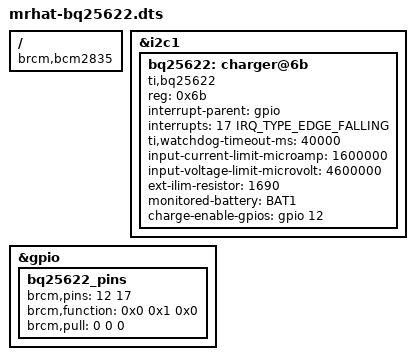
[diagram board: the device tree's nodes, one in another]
/*
* Copyright (C) 2024 Effective Range Kft.
*
* This program is free software; you can redistribute it and/or modify
* it under the terms of the GNU General Public License version 2 as
* published by the Free Software Foundation.
*/
/dts-v1/;
/plugin/;

#include <dt-bindings/gpio/gpio.h>
#include <dt-bindings/interrupt-controller/irq.h>
/ {
    compatible = "brcm,bcm2835";
    
    fragment@0 {
        target = <&i2c1>;
        __overlay__ {
            status = "okay";
            #address-cells = <1>;
            #size-cells = <0>;
            /* BQ25622 */
            bq25622: charger@6b {
                compatible = "ti,bq25622";
                reg = <0x6b>;
                interrupt-parent = <&gpio>;
                interrupts = <17 IRQ_TYPE_EDGE_FALLING>; /* BQ_INT_N */
                interrupt-names = "bqint";
                ti,watchdog-timeout-ms = <40000>;
                input-current-limit-microamp = <1600000>;
                input-voltage-limit-microvolt = <4600000>;
                ext-ilim-resistor = <1690>;
                monitored-battery = <&BAT1>;
                charge-enable-gpios = <&gpio 12 GPIO_ACTIVE_HIGH>;
                status = "okay";
            };
        };
    };

    fragment@1 {
        target = <&gpio>;
        __overlay__ {
            /* set up pin for RTC IRQ */
            bq25622_pins: bq25622_pins {
                brcm,pins = <12 17>;
                brcm,function = <0x0 0x1 0x0>; /* in out in */
                brcm,pull = <0 0 0>; /* none */
            };
        };
    };
    __overrides__ {
        irq_pin = <&bq25622>, "interrupts:0",
                  <&bq25622_pins>, "brcm,pins:4";
        ce_pin = <&bq25622>, "charge-enable-gpios:4",
                 <&bq25622_pins>, "brcm,pins:0";
        wd_timeout = <&bq25622>, "ti,watchdog-timeout-ms:0";
        ce_n = <&bq25622>, "charge-enable-negate?";
        ce_override = <&bq25622>, "charge-enable-override?";
        battery_diag = <&bq25622>, "emit-battery-diag?";
        max_input_uamp = <&bq25622>, "input-current-limit-microamp:0";
        min_input_uvolt = <&bq25622>, "input-voltage-limit-microvolt:0";
        ext_ilim_r = <&bq25622>, "ext-ilim-resistor:0";
    };
};
